# DSS_DISPC register map
Vendor: Texas Instruments
Peripheral module from a debugger description file (folder am437x).
Registers are 32-bit, read-write, no defined reset value unless marked. A register's access mark holds for its fields unless they carry their own. Offsets are as the file gives them; lines under a group give offsets from that group; [hi:lo] are bit positions; {n}, {i} and the like mark numbered series; 'fields as' and 'values as' point back to an identical list; <NAME> marks a mode.

## DSS_DISPC (part 1 of 2)
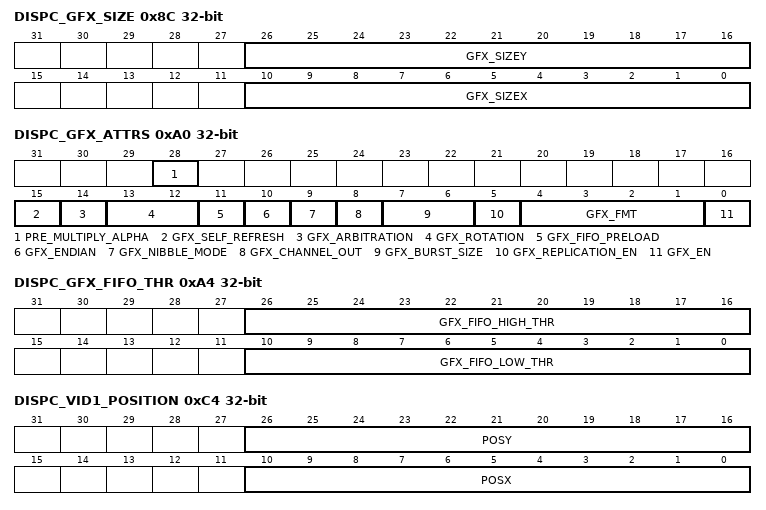
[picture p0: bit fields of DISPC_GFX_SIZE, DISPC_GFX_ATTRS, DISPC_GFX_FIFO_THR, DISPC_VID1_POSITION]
0x8C DISPC_GFX_SIZE — The register configures the size of the graphics window. Shadow register, updated on VFP start period or EVSYNC
  [26:16] GFX_SIZEY — Number of lines of the graphics window. [[br]]Encoded value (from 1 to 2048) to specify the number of lines of the graphics window (program to value minus one)
  [10:0] GFX_SIZEX — Number of pixels of the graphics window. [[br]]Encoded value (from 1 to 2048) to specify the number of pixels per line of the graphics window (program to value minus one)
0xA0 DISPC_GFX_ATTRS — The register configures the graphics attributes. Shadow register, updated on VFP start period or EVSYNC.
  [28] PRE_MULTIPLY_ALPHA — The field configures the DISPC GFX to process incoming data as pre-multiplied alpha data or non premultiplied alpha data. [[br]]Default setting is non pre-multiplied alpha data
    1=en_2_0x1 (Pre-multiplyalpha data color component); 0=en_1_0x0 (Non pre-multiplyalpha data color component)
  [15] GFX_SELF_REFRESH — Enables the self refresh of the graphics window from its own FIFO only
    1=en_2_0x1 (The graphics pipeline does not need anymore to fetch data from memory. Only the graphics FIFO is used. It takes effect after the frame has been loaded in the FIFO); 0=en_1_0x0 (The graphics pipeline accesses the interconnect to fetch data from the system memory)
  [14] GFX_ARBITRATION — Determines the priority of the graphics pipeline. [[br]]The graphics pipeline is one of the high priority pipeline. [[br]]The arbitration wheel gives always the priority first to the high priority pipelines using round-robin between them. [[br]]When there is only normal priority pipelines sending requests, the round-robin applies between them
    1=en_2_0x1 (The graphics pipeline is one of the high priority pipeline); 0=en_1_0x0 (The graphics pipeline is one of the normal priority pipeline)
  [13:12] GFX_ROTATION — Graphics rotation flag (used only in case of RGB24 packed format)
    3=en_4_0x3 (Rotation by 270 degrees); 2=en_3_0x2 (Rotation by 180 degrees); 1=en_2_0x1 (Rotation by 90 degrees); 0=en_1_0x0 (No rotation)
  [11] GFX_FIFO_PRELOAD — Graphics preload value
    1=en_2_0x1 (H/W prefetches pixels up to high threshold value); 0=en_1_0x0 (H/W prefetches pixels up to the preload value defined in the preload register.)
  [10] GFX_ENDIAN — Graphics endianness
    1=en_2_0x1 (Big endian operation is selected); 0=en_1_0x0 (Little endian operation is selected)
  [9] GFX_NIBBLE_MODE — Graphics Nibble Mode (only for 1, 2 and 4 BPP)
    1=en_2_0x1 (Nibble mode is enabled); 0=en_1_0x0 (Nibble mode is disabled)
  [8] GFX_CHANNEL_OUT — Graphics Channel Out configuration
    1=en_2_0x1 (24-bit output selected); 0=en_1_0x0 (LCD output selected)
  [7:6] GFX_BURST_SIZE — Graphics DMA Burst Size
    3=en_4_0x3 (3); 2=en_3_0x2 (16x32bit bursts); 1=en_2_0x1 (8x32bit bursts); 0=en_1_0x0 (4x32bit bursts)
  [5] GFX_REPLICATION_EN — GfxReplicationEnable
    1=en_2_0x1 (Enable Graphics replication logic); 0=en_1_0x0 (Disable Graphics replication logic)
  [4:1] GFX_FMT — Graphics format[[br]] Other enums: Reserved (0x7, 0xA, 0xB and 0xF)
    14=en_12_0xE (RGBx 32 (24-bit RGB aligned on MSB of the 32-bit container)); 13=en_11_0xD (RGBA32); 12=en_10_0xC (ARGB32); 9=en_9_0x9 (RGB 24 (packed in 24-bit container)); 8=en_8_0x8 (RGB 24 (un-packed in 32-bit container)); 6=en_7_0x6 (RGB 16); 5=en_6_0x5 (ARGB16); 4=en_5_0x4 (RGB 12 (un-packed in 16-bit container)); 3=en_4_0x3 (BITMAP 8 (CLUT)); 2=en_3_0x2 (BITMAP 4 (CLUT)); 1=en_2_0x1 (BITMAP 2 (CLUT)); 0=en_1_0x0 (BITMAP 1 (CLUT))
  [0] GFX_EN — GfxEnable
    1=en_2_0x1 (Graphics enabled (graphics pipeline active and graphics window present on the screen)); 0=en_1_0x0 (Graphics disabled (graphics pipeline inactive and graphics window not present))
0xA4 DISPC_GFX_FIFO_THR — The register configures the graphics FIFO. Shadow register, updated on VFP start period or EVSYNC.
  [26:16] GFX_FIFO_HIGH_THR — Graphics FIFO High Threshold Number of bytes defining the threshold value.
  [10:0] GFX_FIFO_LOW_THR — Graphics FIFO Low Threshold Number of bytes defining the threshold value
0xA8 DISPC_GFX_FIFO_SIZE_STS ro — This register defines the graphics FIFO size.
  [10:0] GFX_FIFO_SIZE — Graphics FIFO Size Number of bytes defining the FIFO value.
0xAC DISPC_GFX_ROW_INC — The register configures the number of bytes to increment at the end of the row. Shadow register, updated on VFP start period or EVSYNC
  [31:0] GFX_ROW_INC — Number of bytes to increment at the end of the row Encoded signed value (from (-2^31)-1 to 2^31) to specify the number of bytes to increment at the end of the row in the graphics buffer. [[br]]The value 0 is invalid. [[br]]The value 1 means next pixel. [[br]]The value 1+n*BPP means increment of n pixels. [[br]]The value 1- (n+1)*BPP means decrement of n pixels.
0xB0 DISPC_GFX_PIXEL_INC — The register configures the number of bytes to increment between two pixels. Shadow register, updated on VFP start period or EVSYNC.
  [15:0] GFX_PIXEL_INC — Number of bytes to increment between two pixels Encoded signed value (from (-2^15)-1 to 2^15) to specify the number of bytes between two pixels in the graphics buffer. [[br]]The value 0 is invalid. [[br]]The value 1 means next pixel. [[br]]The value 1+n*BPP means increment of n pixels. [[br]]The value [[br]]1-(n+1)*BPP means decrement of n pixels.
0xB4 DISPC_GFX_WINDOW_SKIP — The register configures the number of bytes to skip during video window display. Shadow register, updated on VFP start period or EVSYNC.
  [31:0] GFX_WINDOW_SKIP — Number of bytes to skip during video window #1. [[br]]Encoded signed value (from (-2^31)-1 to 2^31) to specify the number of bytes to skip in the graphics buffer when video window #1 is displayed on top of the graphics and no transparency color is enabled.
0xB8 DISPC_GFX_TBL_BA — The register configures the base address of the palette buffer or the gamma table buffer. Shadow register, updated on VFP start period or EVSYNC.
  [31:0] GFX_TBL_BA — Base address of the palette/gamma table buffer (24-bit entries in 32- bit containers, aligned on 32-bit boundary).
0xBC DISPC_VID1_BA_0 — The register configures the base address of the video buffer for video window #n(#j for ping-pong mechanism with external trigger, based on the field polarity: 0 for even field and 1 for odd field). Shadow register, updated on VFP start period or EVSYNC.
  [31:0] BA — Video base address Base address of the video buffer (aligned on pixel size boundary)
0xC0 DISPC_VID1_BA_1 — The register configures the base address of the video buffer for video window #n(#j for ping-pong mechanism with external trigger, based on the field polarity: 0 for even field and 1 for odd field). Shadow register, updated on VFP start period or EVSYNC.
  fields as DISPC_VID1_BA_0
0xC4 DISPC_VID1_POSITION — The register configures the position of video window #n. Shadow register, updated on VFP start period or EVSYNC.
  [26:16] POSY — Y position of video window #n Encoded value (from 0 to 2047) to specify the Y position of video window #n. [[br]]The line at the top has the Y-position 0.
  [10:0] POSX — X position of video window #n Encoded value (from 0 to 2047) to specify the X position of video window #n. [[br]]The first pixel on the left of the display screen has the X-position 0.
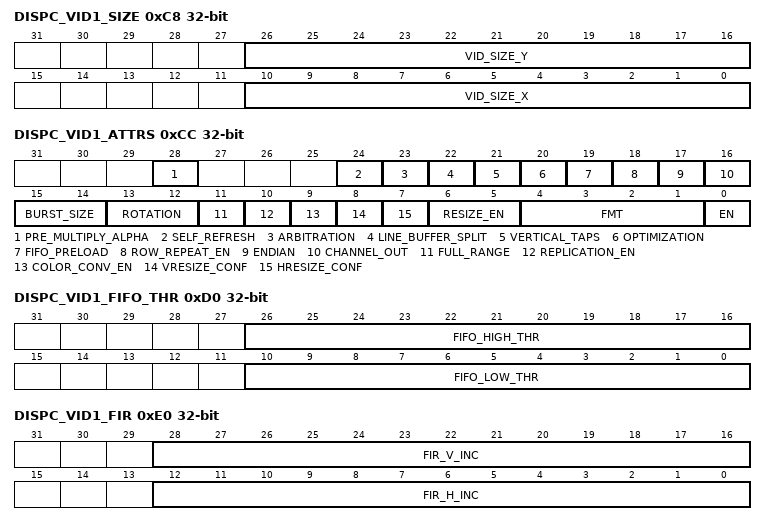
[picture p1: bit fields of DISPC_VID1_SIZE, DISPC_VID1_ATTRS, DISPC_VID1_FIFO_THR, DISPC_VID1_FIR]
0xC8 DISPC_VID1_SIZE — The register configures the size of video window #n. Shadow register, updated on VFP start period or EVSYNC.
  [26:16] VID_SIZE_Y — Number of lines of video #n Encoded value (from 1 to 2048) to specify the number of lines of video window #n (program to value minus one).
  [10:0] VID_SIZE_X — Number of pixels of video window #n Encoded value (from 1 to 2048) to specify the number of pixels of video window #n (program to value minus one).
0xCC DISPC_VID1_ATTRS
  [28] PRE_MULTIPLY_ALPHA — The field configures the DISPC VID2 to process incoming data as pre-multiplied alpha data or non pre-multiplied alpha data. [[br]]Default setting is non pre-multiplied alpha data.
    1=en_2_0x1 (Premultiplyalpha data color component); 0=en_1_0x0 (Non pre-multiplyalpha data color component)
  [24] SELF_REFRESH — Enables the self refresh of the video window from its own FIFO only.
    1=en_2_0x1 (The video pipeline does not need anymore to fetch data from memory. Only the video FIFO is used. It takes effect after the frame has been loaded in the FIFO); 0=en_1_0x0 (The video pipeline accesses the interconnect to fetch data from the system memory)
  [23] ARBITRATION — Determines the priority of the video pipeline. [[br]]The video pipeline is one of the high priority pipeline. [[br]]The arbitration wheel gives always the priority first to the high priority pipelines using round-robin between them. [[br]]When there is only normal priority pipelines sending requests, the round-robin applies between them.
    1=en_2_0x1 (The video pipeline is one of the high priority pipeline); 0=en_1_0x0 (The video pipeline is one of the normal priority pipeline)
  [22] LINE_BUFFER_SPLIT — Video vertical line buffer split
    1=en_2_0x1 (Vertical line buffers are split into two); 0=en_1_0x0 (Vertical line buffers are not split)
  [21] VERTICAL_TAPS — Video vertical resize tap number
    1=en_2_0x1 (Five taps are used for the vertical filtering logic); 0=en_1_0x0 (Three taps are used for the vertical filtering logic. The other two taps are not used)
  [20] OPTIMIZATION — Video optimization in case of
    1=en_2_0x1 (The DMA engine fetches two pixels for each 32-bit OCP request (RGB16 and YUV422) while doing 90- and 270-degree rotation (accessing on-chip memory and off-chip memory). The bit field [21] VIDVERTICALTAPS shall be set to 0x1, bit field [22] VIDLINEBUFFERSPLIT to 0x1, and all scaler registers shall be configured even for 1:1 ratio. Even width is required for the input picture when 5 taps are used.); 0=en_1_0x0 (The DMA engine fetches one pixel for each 32-bit OCP request (RGB16 and YUV422) while doing 90- and 270-degree rotation (accessing on-chip memory and off-chip memory).)
  [19] FIFO_PRELOAD — Video preload value
    1=en_2_0x1 (H/W prefetches pixels up to the high threshold value.); 0=en_1_0x0 (H/W prefetches pixels up to the preload value defined in the preload register)
  [18] ROW_REPEAT_EN — Video Row Repeat (YUV case only when rotating 90 or [[br]]270-degree)
    1=en_2_0x1 (The Row data are fetched twice to extract both the Y components); 0=en_1_0x0 (Row of VIDn won't be read twice)
  [17] ENDIAN — Video Endianness
    1=en_2_0x1 (Big endian operation is selected.); 0=en_1_0x0 (Little endian operation is selected)
  [16] CHANNEL_OUT — Video Channel Out configuration
    1=en_2_0x1 (24 bit output selected); 0=en_1_0x0 (LCD output selected)
  [15:14] BURST_SIZE — Video DMA Burst Size
    values as DISPC_GFX_ATTRS.GFX_BURST_SIZE
  [13:12] ROTATION — Video Rotation Flag
    3=en_4_0x3 (Rotation by 270 degrees); 2=en_3_0x2 (Rotation by 180 degrees); 1=en_2_0x1 (Rotation by 90 degrees); 0=en_1_0x0 (No rotation or VidFormat is RGB)
  [11] FULL_RANGE — VidFullRange
    1=en_2_0x1 (Full range selected: Y is not modified before the color space conversion); 0=en_1_0x0 (Limited range selected: 16 subtracted from Y before color space conversion)
  [10] REPLICATION_EN — VidReplicationEnable
    1=en_2_0x1 (Enable Video replication logic); 0=en_1_0x0 (Disable Video replication logic)
  [9] COLOR_CONV_EN — VidColorConvEnable
    1=en_2_0x1 (Enable Color Space Conversion CbYCr to RGB); 0=en_1_0x0 (Disable Color Space Conversion CbYCr to RGB)
  [8] VRESIZE_CONF — Video Vertical Resize Configuration
    1=en_2_0x1 (Down-sampling selected); 0=en_1_0x0 (Up-sampling selected)
  [7] HRESIZE_CONF — Video Horizontal Resize Configuration
    values as VRESIZE_CONF
  [6:5] RESIZE_EN — Video Resize Enable
    3=en_4_0x3 (Enable both horizontal and vertical resize processing); 2=en_3_0x2 (Enable the vertical resize processing); 1=en_2_0x1 (Enable the horizontal resize processing); 0=en_1_0x0 (Disable the resize processing)
  [4:1] FMT — Video2 channel Format[[br]] Other enums: Reserved (all other values: 0x0 and 0x3, 0x7, and 0xF)
    15=en_16_0xF (RESERVED : 15); 14=en_15_0xE (RGBx 32 (24-bit RGB aligned on MSB of the 32-bit container)); 13=en_14_0xD (RGBA 32); 12=en_13_0xC (ARGB 32); 11=en_12_0xB (UYVY 4:2:2 co-sited); 10=en_11_0xA (YUV2 4:2:2 co-sited); 9=en_10_0x9 (RGB 24 (packed in 24-bit container)); 8=en_9_0x8 (RGB 24 (un-packed in 32-bit container)); 7=en_8_0x7 (RESERVED : 7); 6=en_7_0x6 (RGB 16); 5=en_6_0x5 (ARGB 16); 4=en_5_0x4 (RGB 12 (16-bit container)); {v}=en_{v+1}_{0x0+v} (RESERVED : {v}) (v=0..3)
  [0] EN — VidEnable
    1=en_2_0x1 (Video enabled (video pipeline active and window present on the screen)); 0=en_1_0x0 (Video disabled (video pipeline inactive and window not present))
0xD0 DISPC_VID1_FIFO_THR — The register configures the video FIFO associated with video pipeline #n. Shadow register, updated on VFP start period or EVSYNC.
  [26:16] FIFO_HIGH_THR — Video FIFO high threshold Number of bytes defining the threshold value
  [10:0] FIFO_LOW_THR — Video FIFO low threshold Number of bytes defining the threshold value
0xD4 DISPC_VID1_FIFO_SIZE_STS — The register defines the video FIFO size for video pipeline #n.
  [10:0] FIFO_SIZE — Video FIFO Size Number of bytes defining the FIFO value
0xD8 DISPC_VID1_ROW_INC — The register configures the number of bytes to increment at the end of the row for the buffer associated with video window #n. Shadow register, updated on VFP start period or EVSYNC.
  [31:0] ROW_INC — Number of bytes to increment at the end of the row Encoded signed value (from (-2^31)-1 to 2^31) to specify the number of bytes to increment at the end of the row in the video buffer. [[br]]The value 0 is invalid. [[br]]The value 1 means next pixel. [[br]]The value 1+n*BPP means increment of n pixels. [[br]]The value 1- (n+1)*BPP means decrement of n pixels.
0xDC DISPC_VID1_PIXEL_INC — The register configures the number of bytes to increment between two pixels for the buffer associated with video window #n. Shadow register, updated on VFP start period or EVSYNC
  [15:0] PIXEL_INC — Number of bytes to increment at the end of the row Encoded signed value (from (-2^15)-1 to 2^15) to specify the number of bytes between two pixels in the video buffer. [[br]]The value 0 is invalid. [[br]]The value 1 means next pixel. [[br]]The value 1+n*BPP means increment of n pixels. [[br]]The value [[br]]1-(n+1)*BPP means decrement of n pixels
0xE0 DISPC_VID1_FIR — The register configures the resize factors for horizontal and vertical up-/down-sampling of video window #n. Shadow register, updated on VFP start period or EVSYNC
  [28:16] FIR_V_INC — Vertical increment of the up-/down-sampling filter Encoded value (from 1 to 4096). [[br]]The value 0 is invalid. [[br]]Values greater than 4096 are invalid.
  [12:0] FIR_H_INC — Horizontal increment of the up-/down-sampling filter Encoded value (from 1 to 4096). [[br]]The value 0 is invalid. [[br]]Values greater than 4096 are invalid.
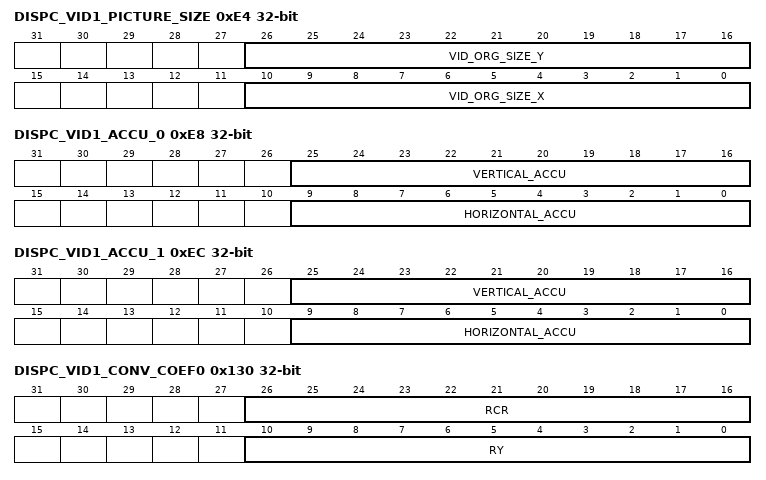
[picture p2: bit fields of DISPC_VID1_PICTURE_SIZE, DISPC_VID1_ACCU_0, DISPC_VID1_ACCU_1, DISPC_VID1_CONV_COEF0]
0xE4 DISPC_VID1_PICTURE_SIZE — The register configures the size of the video picture associated with video layer #nbefore up-/down-scaling. Shadow register, updated on VFP start period or EVSYNC.
  [26:16] VID_ORG_SIZE_Y — Number of lines of the video picture Encoded value (from 1 to 2048) to specify the number of lines of the video picture in memory (program to value minus one)
  [10:0] VID_ORG_SIZE_X — Number of pixels of the video picture Encoded value (from 1 to 2048) to specify the number of pixels of the video picture in memory (program to value minus one). [[br]]The size is limited to the size of the line buffer of the vertical sampling block in case the video picture is processed by the vertical filtering unit.
0xE8 DISPC_VID1_ACCU_0 — The register configures the resize accumulator init values for horizontal and vertical up-/down-sampling of video window #n (#I for ping-pong mechanism with external trigger, based on the field polarity) Shadow register, updated on VFP start period or EVSYNC.
  [25:16] VERTICAL_ACCU — Vertical initialization accu value. [[br]]Encoded value (from 0 to 1023).
  [9:0] HORIZONTAL_ACCU — Horizontal initialization accu value. [[br]]Encoded value (from 0 to 1023).
0xEC DISPC_VID1_ACCU_1 — The register configures the resize accumulator init values for horizontal and vertical up-/down-sampling of video window #n (#I for ping-pong mechanism with external trigger, based on the field polarity) Shadow register, updated on VFP start period or EVSYNC.
  fields as DISPC_VID1_ACCU_0
{0xF0+8i} DISPC_VID1_FIR_COEF_H_{i} access not given (i=0..7)
{0xF4+8i} DISPC_VID1_FIR_COEF_HV_{i} access not given (i=0..7)
0x130 DISPC_VID1_CONV_COEF0 — The register configures the color space conversion matrix coefficients for video pipeline #n. Shadow register, updated on VFP start period or EVSYNC.
  [26:16] RCR — RCr Coefficient Encoded signed value (from -1024 to 1023).
  [10:0] RY — RY Coefficient Encoded signed value (from -1024 to 1023).
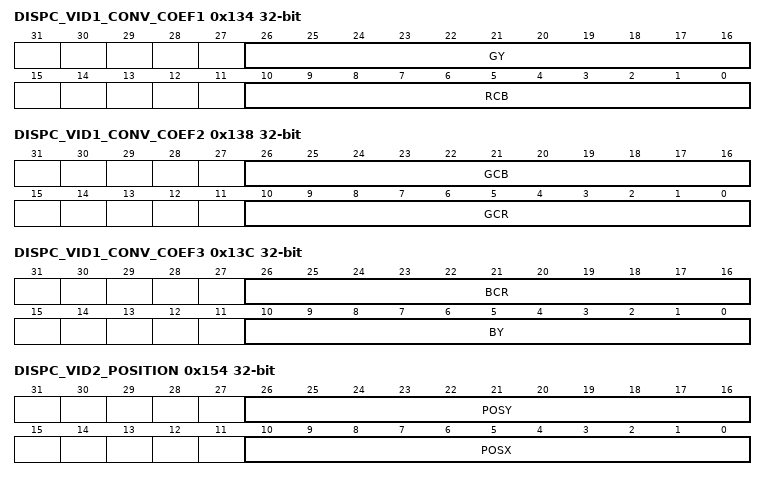
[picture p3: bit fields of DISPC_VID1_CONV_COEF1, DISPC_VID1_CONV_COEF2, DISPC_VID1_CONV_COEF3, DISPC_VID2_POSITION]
0x134 DISPC_VID1_CONV_COEF1 — The register configures the color space conversion matrix coefficients for video pipeline #n. Shadow register, updated on VFP start period or EVSYNC
  [26:16] GY — GY Coefficient Encoded signed value (from -1024 to 1023).
  [10:0] RCB — RCb Coefficient Encoded signed value (from -1024 to 1023)
0x138 DISPC_VID1_CONV_COEF2 — The register configures the color space conversion matrix coefficients for video pipeline #n. Shadow register, updated on VFP start period or EVSYNC.
  [26:16] GCB — GCb Coefficient Encoded signed value (from -1024 to 1023).
  [10:0] GCR — GCr Coefficient Encoded signed value (from -1024 to 1023).
0x13C DISPC_VID1_CONV_COEF3 — The register configures the color space conversion matrix coefficients for video pipeline #n. Shadow register, updated on VFP start period or EVSYNC
  [26:16] BCR — BCr coefficient Encoded signed value (from -1024 to 1023).
  [10:0] BY — BY coefficient Encoded signed value (from -1024 to 1023).
0x140 DISPC_VID1_CONV_COEF4 — The register configures the color space conversion matrix coefficients for video pipeline #n. Shadow register, updated on VFP start period or EVSYNC.
  [10:0] BCB — BCb Coefficient Encoded signed value (from -1024 to 1023).
0x14C DISPC_VID2_BA_0 — The register configures the base address of the video buffer for video window #n(#j for ping-pong mechanism with external trigger, based on the field polarity: 0 for even field and 1 for odd field). Shadow register, updated on VFP start period or EVSYNC.
  fields as DISPC_VID1_BA_0
0x150 DISPC_VID2_BA_1 — The register configures the base address of the video buffer for video window #n(#j for ping-pong mechanism with external trigger, based on the field polarity: 0 for even field and 1 for odd field). Shadow register, updated on VFP start period or EVSYNC.
  fields as DISPC_VID1_BA_0
0x154 DISPC_VID2_POSITION — The register configures the position of video window #n. Shadow register, updated on VFP start period or EVSYNC.
  fields as DISPC_VID1_POSITION
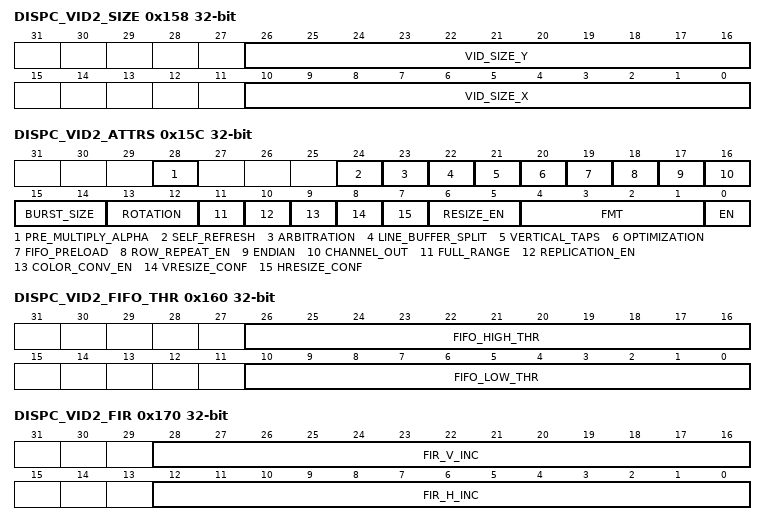
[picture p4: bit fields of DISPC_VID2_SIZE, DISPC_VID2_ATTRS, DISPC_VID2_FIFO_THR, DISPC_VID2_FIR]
0x158 DISPC_VID2_SIZE — The register configures the size of video window #n. Shadow register, updated on VFP start period or EVSYNC.
  fields as DISPC_VID1_SIZE
0x15C DISPC_VID2_ATTRS
  fields as DISPC_VID1_ATTRS
0x160 DISPC_VID2_FIFO_THR — The register configures the video FIFO associated with video pipeline #n. Shadow register, updated on VFP start period or EVSYNC.
  fields as DISPC_VID1_FIFO_THR
0x164 DISPC_VID2_FIFO_SIZE_STS — The register defines the video FIFO size for video pipeline #n.
  fields as DISPC_VID1_FIFO_SIZE_STS
0x168 DISPC_VID2_ROW_INC — The register configures the number of bytes to increment at the end of the row for the buffer associated with video window #n. Shadow register, updated on VFP start period or EVSYNC.
  fields as DISPC_VID1_ROW_INC
0x16C DISPC_VID2_PIXEL_INC — The register configures the number of bytes to increment between two pixels for the buffer associated with video window #n. Shadow register, updated on VFP start period or EVSYNC
  fields as DISPC_VID1_PIXEL_INC
0x170 DISPC_VID2_FIR — The register configures the resize factors for horizontal and vertical up-/down-sampling of video window #n. Shadow register, updated on VFP start period or EVSYNC
  fields as DISPC_VID1_FIR
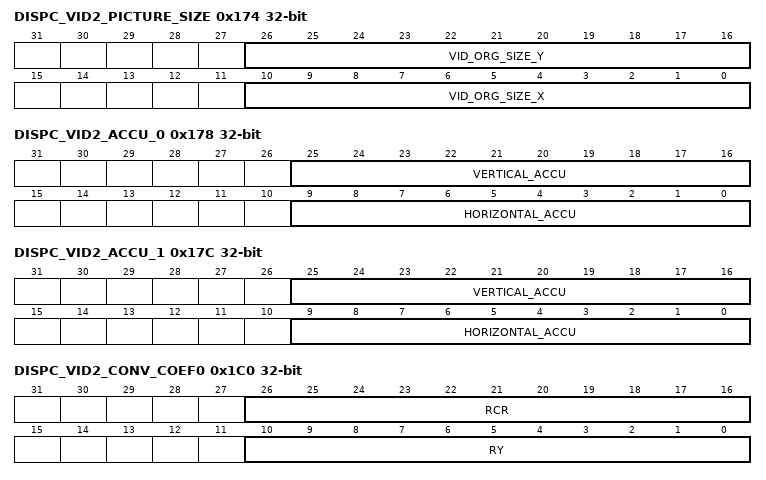
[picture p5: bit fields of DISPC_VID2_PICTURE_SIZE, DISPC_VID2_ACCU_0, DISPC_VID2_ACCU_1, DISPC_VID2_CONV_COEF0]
0x174 DISPC_VID2_PICTURE_SIZE — The register configures the size of the video picture associated with video layer #nbefore up-/down-scaling. Shadow register, updated on VFP start period or EVSYNC.
  fields as DISPC_VID1_PICTURE_SIZE
0x178 DISPC_VID2_ACCU_0 — The register configures the resize accumulator init values for horizontal and vertical up-/down-sampling of video window #n (#I for ping-pong mechanism with external trigger, based on the field polarity) Shadow register, updated on VFP start period or EVSYNC.
  fields as DISPC_VID1_ACCU_0
0x17C DISPC_VID2_ACCU_1 — The register configures the resize accumulator init values for horizontal and vertical up-/down-sampling of video window #n (#I for ping-pong mechanism with external trigger, based on the field polarity) Shadow register, updated on VFP start period or EVSYNC.
  fields as DISPC_VID1_ACCU_0
{0x180+8i} DISPC_VID2_FIR_COEF_H_{i} access not given (i=0..7)
{0x184+8i} DISPC_VID2_FIR_COEF_HV_{i} access not given (i=0..7)
0x1C0 DISPC_VID2_CONV_COEF0 — The register configures the color space conversion matrix coefficients for video pipeline #n. Shadow register, updated on VFP start period or EVSYNC.
  fields as DISPC_VID1_CONV_COEF0
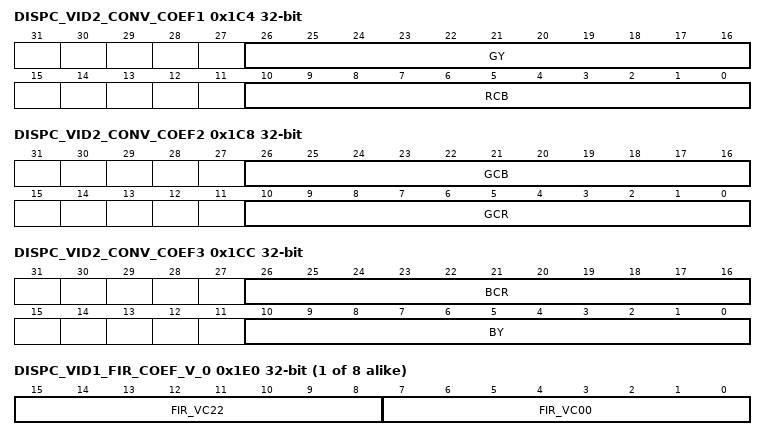
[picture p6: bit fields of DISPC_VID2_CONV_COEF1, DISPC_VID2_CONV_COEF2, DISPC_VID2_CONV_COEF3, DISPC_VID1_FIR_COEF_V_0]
0x1C4 DISPC_VID2_CONV_COEF1 — The register configures the color space conversion matrix coefficients for video pipeline #n. Shadow register, updated on VFP start period or EVSYNC
  fields as DISPC_VID1_CONV_COEF1
0x1C8 DISPC_VID2_CONV_COEF2 — The register configures the color space conversion matrix coefficients for video pipeline #n. Shadow register, updated on VFP start period or EVSYNC.
  fields as DISPC_VID1_CONV_COEF2
0x1CC DISPC_VID2_CONV_COEF3 — The register configures the color space conversion matrix coefficients for video pipeline #n. Shadow register, updated on VFP start period or EVSYNC
  fields as DISPC_VID1_CONV_COEF3
0x1D0 DISPC_VID2_CONV_COEF4 — The register configures the color space conversion matrix coefficients for video pipeline #n. Shadow register, updated on VFP start period or EVSYNC.
  fields as DISPC_VID1_CONV_COEF4
{0x1D4+4i} DISPC_DATA_CYCLE_{i} access not given (i=0..2)
{0x1E0+4i} DISPC_VID1_FIR_COEF_V_{i} (i=0..7) — This bank of registers configures the down/up/down-scaling coefficients for the vertical resize of the video picture associated with video window #n for phases 0 to 7. Shadow register, updated on VFP start period or EVSYNC.
  [15:8] FIR_VC22 — Signed coefficient C22 for vertical up/down-scaling with phase n
  [7:0] FIR_VC00 — Signed coefficient C00 for vertical up/down-scaling with phase n
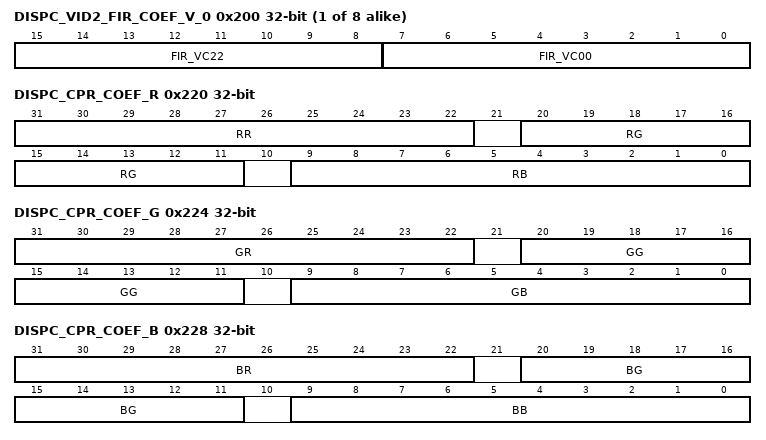
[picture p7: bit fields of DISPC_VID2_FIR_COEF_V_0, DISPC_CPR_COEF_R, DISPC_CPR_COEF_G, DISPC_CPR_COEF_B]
{0x200+4i} DISPC_VID2_FIR_COEF_V_{i} (i=0..7) — This bank of registers configures the down/up/down-scaling coefficients for the vertical resize of the video picture associated with video window #n for phases 0 to 7. Shadow register, updated on VFP start period or EVSYNC.
  fields as DISPC_VID1_FIR_COEF_V_0
0x220 DISPC_CPR_COEF_R — This register configures the color phase rotation matrix coefficients for the red component. Shadow register, updated on VFP start period.
  [31:22] RR — RR coefficient Encoded signed value (from -512 to 511)
  [20:11] RG — RG coefficient Encoded signed value (from -512 to 511)
  [9:0] RB — RB coefficient Encoded signed value (from -512 to 511)
0x224 DISPC_CPR_COEF_G — This register configures the color phase rotation matrix coefficients for the green component. Shadow register, updated on VFP start period
  [31:22] GR — GR coefficient Encoded signed value (from -512 to 511)
  [20:11] GG — GG coefficient Encoded signed value (from -512 to 511)
  [9:0] GB — GB coefficient Encoded signed value (from -512 to 511)
0x228 DISPC_CPR_COEF_B — This register configures the color phase rotation matrix coefficients for the blue component. Shadow register, updated on VFP start period.
  [31:22] BR — BR coefficient Encoded signed value (from -512 to 511)
  [20:11] BG — BG coefficient Encoded signed value (from -512 to 511)
  [9:0] BB — BB coefficient Encoded signed value (from -512 to 511)
0x22C DISPC_GFX_PRELOAD — This register configures the graphics FIFO. Shadow register, updated on VFP start period or EVSYNC.
  [11:0] PRELOAD — Graphics preload value: Number of bytes defining the preload value. [[br]]Constraint: Maximum value is (FIFO size - DMA burst size - 8) bytes
0x230 DISPC_VID1_PRELOAD — This register configures the video FIFO. Shadow register, updated on VFP start period or EVSYNC.
  [11:0] PRELOAD — Video preload value: Number of bytes defining the preload value. [[br]]Constraint: Maximum value is (FIFO size - DMA burst size - 8) bytes
0x234 DISPC_VID2_PRELOAD — This register configures the video FIFO. Shadow register, updated on VFP start period or EVSYNC.
  fields as DISPC_VID1_PRELOAD
